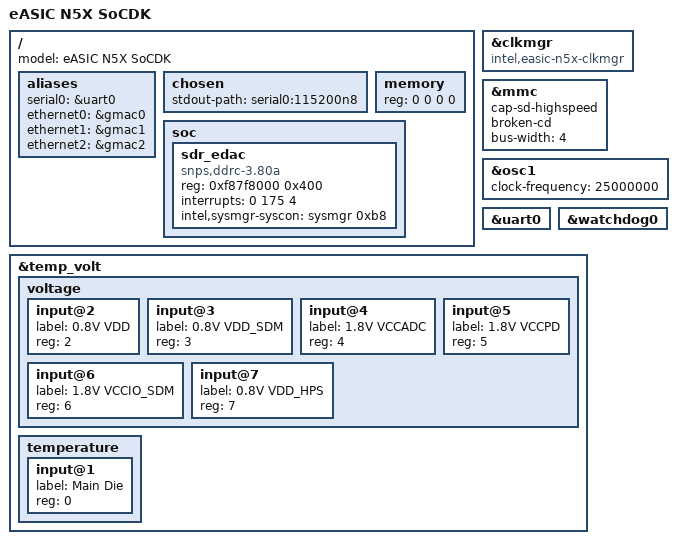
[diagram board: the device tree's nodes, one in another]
// SPDX-License-Identifier:     GPL-2.0
/*
 * Copyright (C) 2021, Intel Corporation
 */
#include "socfpga_agilex.dtsi"

/ {
	model = "eASIC N5X SoCDK";

	aliases {
		serial0 = &uart0;
		ethernet0 = &gmac0;
		ethernet1 = &gmac1;
		ethernet2 = &gmac2;
	};

	chosen {
		stdout-path = "serial0:115200n8";
	};

	memory {
		device_type = "memory";
		/* We expect the bootloader to fill in the reg */
		reg = <0 0 0 0>;
	};

	soc {
		sdr_edac {
			compatible = "snps,ddrc-3.80a";
			reg = <0xf87f8000 0x400>;
			interrupts = <0 175 4>;
			intel,sysmgr-syscon = <&sysmgr 0xb8>;
		};
	};
};

&clkmgr {
	compatible = "intel,easic-n5x-clkmgr";
};

&mmc {
	status = "okay";
	cap-sd-highspeed;
	broken-cd;
	bus-width = <4>;
};

&osc1 {
	clock-frequency = <25000000>;
};

&uart0 {
	status = "okay";
};

&watchdog0 {
	status = "okay";
};

&temp_volt {
	voltage {
		#address-cells = <1>;
		#size-cells = <0>;
		input@2 {
			label = "0.8V VDD";
			reg = <2>;
		};

		input@3 {
			label = "0.8V VDD_SDM";
			reg = <3>;
		};

		input@4 {
			label = "1.8V VCCADC";
			reg = <4>;
		};

		input@5 {
			label = "1.8V VCCPD";
			reg = <5>;
		};

		input@6 {
			label = "1.8V VCCIO_SDM";
			reg = <6>;
		};

		input@7 {
			label = "0.8V VDD_HPS";
			reg = <7>;
		};
	};

	temperature {
		#address-cells = <1>;
		#size-cells = <0>;

		input@1 {
			label = "Main Die";
			reg = <0>;
		};
	};
};
